# ATmega649A device description
Architecture: AVR8; Family: megaAVR
Registers are 8-bit, access not given, no defined reset value unless marked. A register's access mark holds for its fields unless they carry their own. Offsets are from the block's base; [hi:lo] are bit positions; {n}, {i} and the like mark numbered series.

## LOCKBIT — Lockbits
Instances: LOCKBIT 0 in lockbits
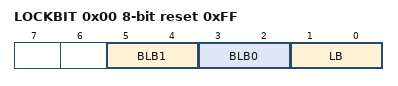
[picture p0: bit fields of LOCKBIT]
0x00 LOCKBIT reset 0xFF
  [5:4] BLB1 — Boot Loader Protection Mode
    0=LPM_SPM_DISABLE (LPM and SPM prohibited in Boot Section); 1=LPM_DISABLE (LPM prohibited in Boot Section); 2=SPM_DISABLE (SPM prohibited in Boot Section); 3=NO_LOCK (No lock on SPM and LPM in Boot Section)
  [3:2] BLB0 — Boot Loader Protection Mode
    0=LPM_SPM_DISABLE (LPM and SPM prohibited in Application Section); 1=LPM_DISABLE (LPM prohibited in Application Section); 2=SPM_DISABLE (SPM prohibited in Application Section); 3=NO_LOCK (No lock on SPM and LPM in Application Section)
  [1:0] LB — Memory Lock
    0=PROG_VER_DISABLED (Further programming and verification disabled); 2=PROG_DISABLED (Further programming disabled); 3=NO_LOCK (No memory lock features enabled)

## ADC — Analog-to-Digital Converter
Instances: ADC 0x00
0x78 ADC 16-bit — ADC Data Register Bytes
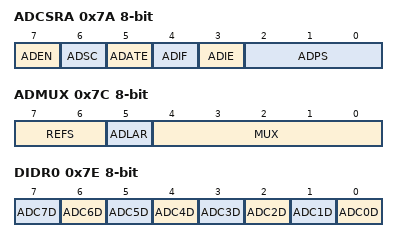
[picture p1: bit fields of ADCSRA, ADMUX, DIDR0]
0x7A ADCSRA — The ADC Control and Status register
  [7] ADEN — ADC Enable
  [6] ADSC — ADC Start Conversion
  [5] ADATE — ADC Auto Trigger Enable
  [4] ADIF — ADC Interrupt Flag
  [3] ADIE — ADC Interrupt Enable
  [2:0] ADPS — ADC Prescaler Select Bits
    0=2; 1=2; 2=4; 3=8; 4=16; 5=32; 6=64; 7=128
0x7B ADCSRB — ADC Control and Status Register B
  [2:0] ADTS — ADC Auto Trigger Sources
0x7C ADMUX — The ADC multiplexer Selection Register
  [7:6] REFS — Reference Selection Bits
    0=AREF, Internal Vref turned off; 1=AVCC with external capacitor at AREF pin; 3=Internal 1.1V Voltage Reference with external capacitor at AREF pin
  [5] ADLAR — Left Adjust Result
  [4:0] MUX — Analog Channel and Gain Selection Bits
0x7E DIDR0 — Digital Input Disable Register 0
  [n] ADC{n}D (n=0..7) — ADC{n} Digital input Disable

## AC — Analog Comparator
Instances: AC 0x00
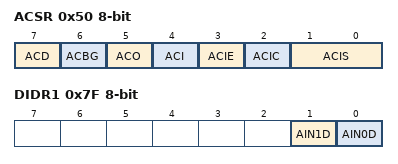
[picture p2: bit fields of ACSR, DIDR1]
0x50 ACSR — Analog Comparator Control And Status Register
  [7] ACD — Analog Comparator Disable
  [6] ACBG — Analog Comparator Bandgap Select
  [5] ACO — Analog Compare Output
  [4] ACI — Analog Comparator Interrupt Flag
  [3] ACIE — Analog Comparator Interrupt Enable
  [2] ACIC — Analog Comparator Input Capture Enable
  [1:0] ACIS — Analog Comparator Interrupt Mode Select bits
    0=Interrupt on Toggle; 2=Interrupt on Falling Edge; 3=Interrupt on Rising Edge
0x7B ADCSRB — ADC Control and Status Register B
  [6] ACME — Analog Comparator Multiplexer Enable
0x7F DIDR1 — Digital Input Disable Register 1
  [1] AIN1D — AIN1 Digital Input Disable
  [0] AIN0D — AIN0 Digital Input Disable

## SPI — Serial Peripheral Interface
Instances: SPI 0x00
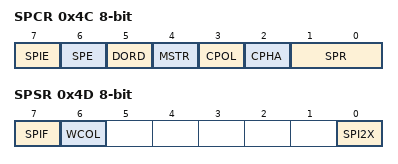
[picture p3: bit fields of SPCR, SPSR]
0x4C SPCR — SPI Control Register
  [7] SPIE — SPI Interrupt Enable
  [6] SPE — SPI Enable
  [5] DORD — Data Order
  [4] MSTR — Master/Slave Select
  [3] CPOL — Clock polarity
  [2] CPHA — Clock Phase
  [1:0] SPR — SPI Clock Rate Selects
    0=fosc/4; 1=fosc/16; 2=fosc/64; 3=fosc/128; 4=fosc/2; 5=fosc/8; 6=fosc/32; 7=fosc/64
0x4D SPSR — SPI Status Register
  [7] SPIF — SPI Interrupt Flag
  [6] WCOL — Write Collision Flag
  [0] SPI2X — Double SPI Speed Bit
0x4E SPDR — SPI Data Register

## USI — Universal Serial Interface
Instances: USI 0x00
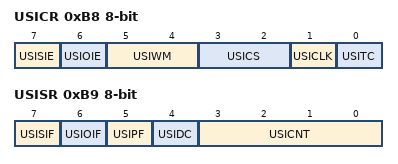
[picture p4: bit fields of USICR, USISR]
0xB8 USICR — USI Control Register
  [7] USISIE — Start Condition Interrupt Enable
  [6] USIOIE — Counter Overflow Interrupt Enable
  [5:4] USIWM — USI Wire Mode Bits
    0=Normal Operation; 1=Three-Wire Mode; 2=Two-Wire Mode; 3=Two-Wire Mode Held Low
  [3:2] USICS — USI Clock Source Select Bits
  [1] USICLK — Clock Strobe
  [0] USITC — Toggle Clock Port Pin
0xB9 USISR — USI Status Register
  [7] USISIF — Start Condition Interrupt Flag
  [6] USIOIF — Counter Overflow Interrupt Flag
  [5] USIPF — Stop Condition Flag
  [4] USIDC — Data Output Collision
  [3:0] USICNT — USI Counter Value Bits
0xBA USIDR — USI Data Register
